# R7FA6M1AD register map
Vendor: Renesas; Series: RA6; File version: 1.2
CPU: CM4 r0p1, little endian, MPU, FPU, VTOR, 4 interrupt priority bits
Registers are 8-bit, read-write, reset 0x0 unless marked. A register's access mark holds for its fields unless they carry their own. Offsets are from the block's base; [hi:lo] are bit positions.

## AGT0 — Asynchronous General purpose Timer 0
Base 0x40084000
Same registers: AGT1 0x40084100
0x00 AGT 16-bit reset 0xFFFF — AGT Counter Register
  [15:0] AGT — 16bit counter and reload registerNOTE : When 1 is written to the TSTOP bit in the AGTCRn register, the 16-bit counter is forcibly stopped and set to FFFFH.
0x02 AGTCMA 16-bit reset 0xFFFF — AGT Compare Match A Register
  [15:0] AGTCMA — AGT Compare Match A RegisterNOTE : When 1 is written to the TSTOP bit in the AGTCRn register, set to FFFFH
0x04 AGTCMB 16-bit reset 0xFFFF — AGT Compare Match B Register
  [15:0] AGTCMB — AGT Compare Match B RegisterNOTE : When 1 is written to the TSTOP bit in the AGTCR register, set to FFFFH
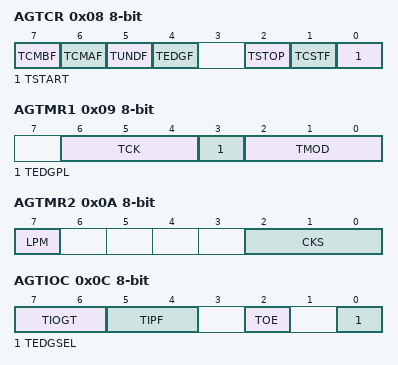
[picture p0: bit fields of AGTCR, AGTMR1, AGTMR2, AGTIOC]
0x08 AGTCR — AGT Control Register
  [7] TCMBF write-0-clears read-modifies — AGT compare match B flag
  [6] TCMAF write-0-clears read-modifies — AGT compare match A flag
  [5] TUNDF write-0-clears read-modifies — AGT underflow flag
  [4] TEDGF write-0-clears read-modifies — Active edge judgement flag
  [2] TSTOP wo — AGT count forced stop
  [1] TCSTF ro — AGT count status flag
  [0] TSTART — AGT count start
0x09 AGTMR1 — AGT Mode Register 1
  [6:4] TCK — AGT count source select
  [3] TEDGPL — AGTIO edge polarity select
  [2:0] TMOD — AGT operating mode select
0x0A AGTMR2 — AGT Mode Register 2
  [7] LPM — AGT Low Power Mode
  [2:0] CKS — fsub/LOCO count source clock frequency division ratio select
0x0C AGTIOC — AGT I/O Control Register
  [7:6] TIOGT — AGTIO count control
  [5:4] TIPF — AGTIO input filter select
  [2] TOE — AGTO output enable
  [0] TEDGSEL — I/O polarity switchFunction varies depending on the operating mode.
0x0D AGTISR — AGT Event Pin Select Register
  [2] EEPS — AGTEE polarty selection
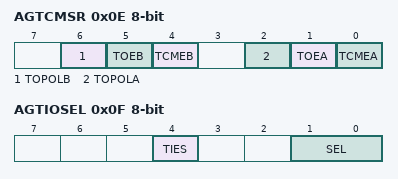
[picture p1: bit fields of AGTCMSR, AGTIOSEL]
0x0E AGTCMSR — AGT Compare Match Function Select Register
  [6] TOPOLB — AGTOB polarity select
  [5] TOEB — AGTOB output enable
  [4] TCMEB — Compare match B register enable
  [2] TOPOLA — AGTOA polarity select
  [1] TOEA — AGTOA output enable
  [0] TCMEA — Compare match A register enable
0x0F AGTIOSEL — AGT Pin Select Register
  [4] TIES — AGTIO input enable
  [1:0] SEL — AGTIO pin select

## GPT_OPS — Output Phase Switching Controller
Base 0x40078FF0
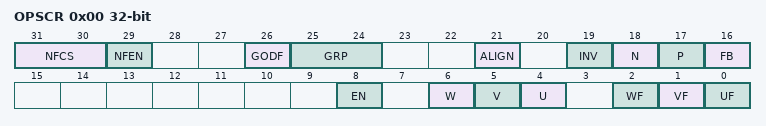
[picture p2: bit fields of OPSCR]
0x00 OPSCR 32-bit — Output Phase Switching Control Register
  [31:30] NFCS — External Input Noise Filter Clock selectionNoise filter sampling clock setting of the external input.
  [29] NFEN — External Input Noise Filter Enable
  [26] GODF — Group output disable function
  [25:24] GRP — Output disabled source selection
  [21] ALIGN — Input phase alignment
  [19] INV — Invert,Phase Output Control
  [18] N — Negative,Phase Output (N) Control
  [17] P — Positive,Phase Output (P) Control
  [16] FB — External Feedback Signal EnableThis bit selects the input phase from the software settings and external input.
  [8] EN — Enable,Phase Output Control
  [6] W ro — Input W,Phase MonitorThis bit monitors the state of the input phase.OPSCR.FB=0:External input monitoring by PCLKOPSCR.FB=1:Software settings (UF/VF/WF)
  [5] V ro — Input V,Phase MonitorThis bit monitors the state of the input phase.OPSCR.FB=0:External input monitoring by PCLKOPSCR.FB=1:Software settings (UF/VF/WF)
  [4] U ro — Input U,Phase MonitorThis bit monitors the state of the input phase.OPSCR.FB=0:External input monitoring by PCLKOPSCR.FB=1:Software settings (UF/VF/WF)
  [2] WF — Input Phase Soft Setting UFThis bit sets the input phase by the software settings.This bit setting is valid when the OPSCR.FB bit = 1.
  [1] VF — Input Phase Soft Setting VFThis bit sets the input phase by the software settings.This bit setting is valid when the OPSCR.FB bit = 1.
  [0] UF — Input Phase Soft Setting WFThis bit sets the input phase by the software settings.This bit setting is valid when the OPSCR.FB bit = 1.
